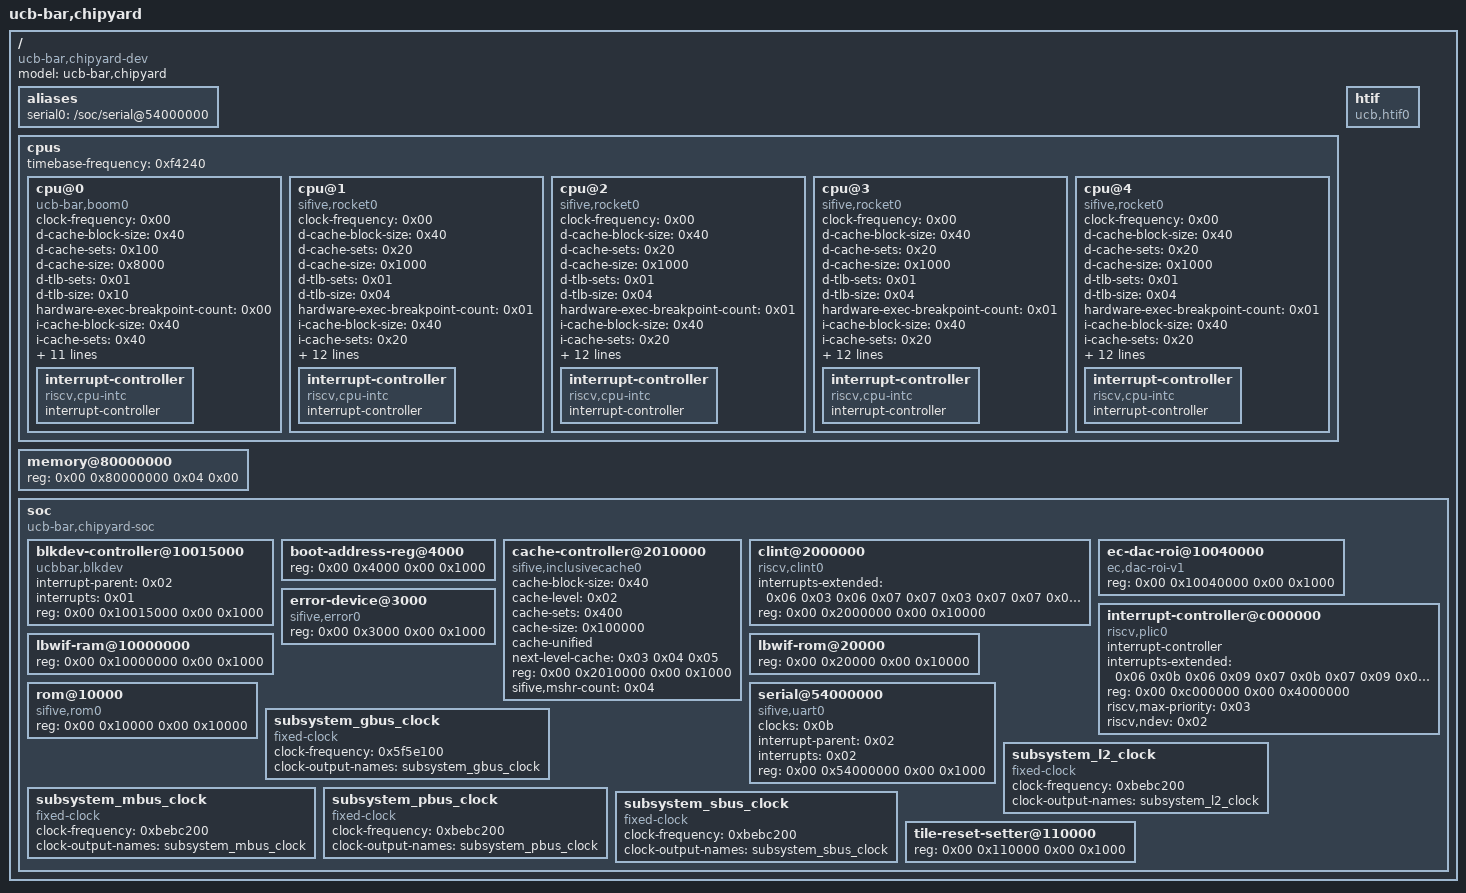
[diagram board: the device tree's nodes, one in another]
/dts-v1/;

/ {
	#address-cells = <0x02>;
	#size-cells = <0x02>;
	compatible = "ucb-bar,chipyard-dev";
	model = "ucb-bar,chipyard";

	aliases {
		serial0 = "/soc/serial@54000000";
	};

	cpus {
		#address-cells = <0x01>;
		#size-cells = <0x00>;
		timebase-frequency = <0xf4240>;

		cpu@0 {
			clock-frequency = <0x00>;
			compatible = "ucb-bar,boom0\0riscv";
			d-cache-block-size = <0x40>;
			d-cache-sets = <0x100>;
			d-cache-size = <0x8000>;
			d-tlb-sets = <0x01>;
			d-tlb-size = <0x10>;
			device_type = "cpu";
			hardware-exec-breakpoint-count = <0x00>;
			i-cache-block-size = <0x40>;
			i-cache-sets = <0x40>;
			i-cache-size = <0x8000>;
			i-tlb-sets = <0x01>;
			i-tlb-size = <0x20>;
			mmu-type = "riscv,sv39";
			next-level-cache = <0x01>;
			reg = <0x00>;
			riscv,isa = "rv64imafdcZicsr_Zifencei_Zihpm";
			riscv,pmpgranularity = <0x04>;
			riscv,pmpregions = <0x08>;
			status = "okay";
			timebase-frequency = <0xf4240>;
			tlb-split;

			interrupt-controller {
				#interrupt-cells = <0x01>;
				compatible = "riscv,cpu-intc";
				interrupt-controller;
				phandle = <0x06>;
			};
		};

		cpu@1 {
			clock-frequency = <0x00>;
			compatible = "sifive,rocket0\0riscv";
			d-cache-block-size = <0x40>;
			d-cache-sets = <0x20>;
			d-cache-size = <0x1000>;
			d-tlb-sets = <0x01>;
			d-tlb-size = <0x04>;
			device_type = "cpu";
			hardware-exec-breakpoint-count = <0x01>;
			i-cache-block-size = <0x40>;
			i-cache-sets = <0x20>;
			i-cache-size = <0x1000>;
			i-tlb-sets = <0x01>;
			i-tlb-size = <0x20>;
			mmu-type = "riscv,sv39";
			next-level-cache = <0x01>;
			reg = <0x01>;
			riscv,isa = "rv64imafdcZicsr_Zifencei_Zihpm_Xrocket";
			riscv,pmpgranularity = <0x04>;
			riscv,pmpregions = <0x08>;
			status = "okay";
			timebase-frequency = <0xf4240>;
			tlb-split;

			interrupt-controller {
				#interrupt-cells = <0x01>;
				compatible = "riscv,cpu-intc";
				interrupt-controller;
				phandle = <0x07>;
			};
		};

		cpu@2 {
			clock-frequency = <0x00>;
			compatible = "sifive,rocket0\0riscv";
			d-cache-block-size = <0x40>;
			d-cache-sets = <0x20>;
			d-cache-size = <0x1000>;
			d-tlb-sets = <0x01>;
			d-tlb-size = <0x04>;
			device_type = "cpu";
			hardware-exec-breakpoint-count = <0x01>;
			i-cache-block-size = <0x40>;
			i-cache-sets = <0x20>;
			i-cache-size = <0x1000>;
			i-tlb-sets = <0x01>;
			i-tlb-size = <0x20>;
			mmu-type = "riscv,sv39";
			next-level-cache = <0x01>;
			reg = <0x02>;
			riscv,isa = "rv64imafdcZicsr_Zifencei_Zihpm_Xrocket";
			riscv,pmpgranularity = <0x04>;
			riscv,pmpregions = <0x08>;
			status = "okay";
			timebase-frequency = <0xf4240>;
			tlb-split;

			interrupt-controller {
				#interrupt-cells = <0x01>;
				compatible = "riscv,cpu-intc";
				interrupt-controller;
				phandle = <0x08>;
			};
		};

		cpu@3 {
			clock-frequency = <0x00>;
			compatible = "sifive,rocket0\0riscv";
			d-cache-block-size = <0x40>;
			d-cache-sets = <0x20>;
			d-cache-size = <0x1000>;
			d-tlb-sets = <0x01>;
			d-tlb-size = <0x04>;
			device_type = "cpu";
			hardware-exec-breakpoint-count = <0x01>;
			i-cache-block-size = <0x40>;
			i-cache-sets = <0x20>;
			i-cache-size = <0x1000>;
			i-tlb-sets = <0x01>;
			i-tlb-size = <0x20>;
			mmu-type = "riscv,sv39";
			next-level-cache = <0x01>;
			reg = <0x03>;
			riscv,isa = "rv64imafdcZicsr_Zifencei_Zihpm_Xrocket";
			riscv,pmpgranularity = <0x04>;
			riscv,pmpregions = <0x08>;
			status = "okay";
			timebase-frequency = <0xf4240>;
			tlb-split;

			interrupt-controller {
				#interrupt-cells = <0x01>;
				compatible = "riscv,cpu-intc";
				interrupt-controller;
				phandle = <0x09>;
			};
		};

		cpu@4 {
			clock-frequency = <0x00>;
			compatible = "sifive,rocket0\0riscv";
			d-cache-block-size = <0x40>;
			d-cache-sets = <0x20>;
			d-cache-size = <0x1000>;
			d-tlb-sets = <0x01>;
			d-tlb-size = <0x04>;
			device_type = "cpu";
			hardware-exec-breakpoint-count = <0x01>;
			i-cache-block-size = <0x40>;
			i-cache-sets = <0x20>;
			i-cache-size = <0x1000>;
			i-tlb-sets = <0x01>;
			i-tlb-size = <0x20>;
			mmu-type = "riscv,sv39";
			next-level-cache = <0x01>;
			reg = <0x04>;
			riscv,isa = "rv64imafdcZicsr_Zifencei_Zihpm_Xrocket";
			riscv,pmpgranularity = <0x04>;
			riscv,pmpregions = <0x08>;
			status = "okay";
			timebase-frequency = <0xf4240>;
			tlb-split;

			interrupt-controller {
				#interrupt-cells = <0x01>;
				compatible = "riscv,cpu-intc";
				interrupt-controller;
				phandle = <0x0a>;
			};
		};
	};

	htif {
		compatible = "ucb,htif0";
	};

	memory@80000000 {
		device_type = "memory";
		phandle = <0x03>;
		reg = <0x00 0x80000000 0x04 0x00>;
	};

	soc {
		#address-cells = <0x02>;
		#size-cells = <0x02>;
		compatible = "ucb-bar,chipyard-soc\0simple-bus";
		ranges;

		blkdev-controller@10015000 {
			compatible = "ucbbar,blkdev";
			interrupt-parent = <0x02>;
			interrupts = <0x01>;
			reg = <0x00 0x10015000 0x00 0x1000>;
			reg-names = "control";
		};

		boot-address-reg@4000 {
			reg = <0x00 0x4000 0x00 0x1000>;
			reg-names = "control";
		};

		cache-controller@2010000 {
			cache-block-size = <0x40>;
			cache-level = <0x02>;
			cache-sets = <0x400>;
			cache-size = <0x100000>;
			cache-unified;
			compatible = "sifive,inclusivecache0\0cache";
			next-level-cache = <0x03 0x04 0x05>;
			phandle = <0x01>;
			reg = <0x00 0x2010000 0x00 0x1000>;
			reg-names = "control";
			sifive,mshr-count = <0x04>;
		};

		clint@2000000 {
			compatible = "riscv,clint0";
			interrupts-extended = <0x06 0x03 0x06 0x07 0x07 0x03 0x07 0x07 0x08 0x03 0x08 0x07 0x09 0x03 0x09 0x07 0x0a 0x03 0x0a 0x07>;
			reg = <0x00 0x2000000 0x00 0x10000>;
			reg-names = "control";
		};

		ec-dac-roi@10040000 {
			compatible = "ec,dac-roi-v1";
			reg = <0x00 0x10040000 0x00 0x1000>;
			reg-names = "control";
		};

		error-device@3000 {
			compatible = "sifive,error0";
			reg = <0x00 0x3000 0x00 0x1000>;
		};

		interrupt-controller@c000000 {
			#interrupt-cells = <0x01>;
			compatible = "riscv,plic0";
			interrupt-controller;
			interrupts-extended = <0x06 0x0b 0x06 0x09 0x07 0x0b 0x07 0x09 0x08 0x0b 0x08 0x09 0x09 0x0b 0x09 0x09 0x0a 0x0b 0x0a 0x09>;
			phandle = <0x02>;
			reg = <0x00 0xc000000 0x00 0x4000000>;
			reg-names = "control";
			riscv,max-priority = <0x03>;
			riscv,ndev = <0x02>;
		};

		lbwif-ram@10000000 {
			phandle = <0x04>;
			reg = <0x00 0x10000000 0x00 0x1000>;
		};

		lbwif-rom@20000 {
			phandle = <0x05>;
			reg = <0x00 0x20000 0x00 0x10000>;
		};

		rom@10000 {
			compatible = "sifive,rom0";
			reg = <0x00 0x10000 0x00 0x10000>;
			reg-names = "mem";
		};

		serial@54000000 {
			clocks = <0x0b>;
			compatible = "sifive,uart0";
			interrupt-parent = <0x02>;
			interrupts = <0x02>;
			reg = <0x00 0x54000000 0x00 0x1000>;
			reg-names = "control";
		};

		subsystem_gbus_clock {
			#clock-cells = <0x00>;
			clock-frequency = <0x5f5e100>;
			clock-output-names = "subsystem_gbus_clock";
			compatible = "fixed-clock";
		};

		subsystem_l2_clock {
			#clock-cells = <0x00>;
			clock-frequency = <0xbebc200>;
			clock-output-names = "subsystem_l2_clock";
			compatible = "fixed-clock";
		};

		subsystem_mbus_clock {
			#clock-cells = <0x00>;
			clock-frequency = <0xbebc200>;
			clock-output-names = "subsystem_mbus_clock";
			compatible = "fixed-clock";
		};

		subsystem_pbus_clock {
			#clock-cells = <0x00>;
			clock-frequency = <0xbebc200>;
			clock-output-names = "subsystem_pbus_clock";
			compatible = "fixed-clock";
			phandle = <0x0b>;
		};

		subsystem_sbus_clock {
			#clock-cells = <0x00>;
			clock-frequency = <0xbebc200>;
			clock-output-names = "subsystem_sbus_clock";
			compatible = "fixed-clock";
		};

		tile-reset-setter@110000 {
			reg = <0x00 0x110000 0x00 0x1000>;
			reg-names = "control";
		};
	};
};
